AUTOSAR XML (schema 00047)
package /SWC_DEM
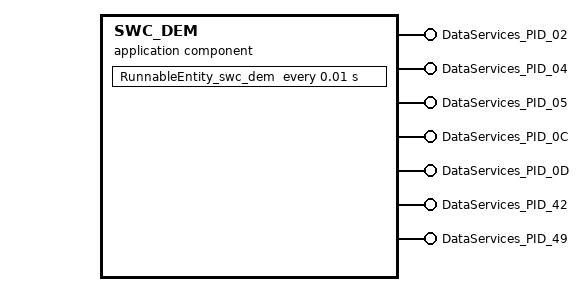
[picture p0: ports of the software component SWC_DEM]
  application sw component type SWC_DEM
    7 x provide port:
      DataServices_PID_02: provided-interface=DataServices_PID_02
      DataServices_PID_04: provided-interface=DataServices_PID_04
      DataServices_PID_05: provided-interface=DataServices_PID_05
      DataServices_PID_0C: provided-interface=DataServices_PID_0C
      DataServices_PID_0D: provided-interface=DataServices_PID_0D
      DataServices_PID_42: provided-interface=DataServices_PID_42
      DataServices_PID_49: provided-interface=DataServices_PID_49
    behavior IB_SWC_DEM
      timing event TimingEvent_SWC_DEM: start-on-event=RunnableEntity_swc_dem, period=0.01
      7 x operation invoked event:
        OperationInvokedEvent_PID_02: start-on-event=ASW_DEM_DataServices_Dem_PID_02, operation=DataServices_PID_02.ReadData
        OperationInvokedEvent_PID_0D: start-on-event=ASW_DEM_DataServices_Dem_PID_0D, operation=DataServices_PID_0D.ReadData
        OperationInvokedEvent_PID_42: start-on-event=ASW_DEM_DataServices_Dem_PID_42, operation=DataServices_PID_42.ReadData
        OperationInvokedEvent_PID_49: start-on-event=ASW_DEM_DataServices_Dem_PID_49, operation=DataServices_PID_49.ReadData
        OperationInvokedEvent_PID_05: start-on-event=ASW_DEM_DataServices_Dem_PID_05, operation=DataServices_PID_05.ReadData
        OperationInvokedEvent_PID_04: start-on-event=ASW_DEM_DataServices_Dem_PID_04, operation=DataServices_PID_04.ReadData
        OperationInvokedEvent_PID_0C: start-on-event=ASW_DEM_DataServices_Dem_PID_0C, operation=DataServices_PID_0C.ReadData
      8 x runnable:
        ASW_DEM_DataServices_Dem_PID_02: symbol=ASW_DEM_DataServices_DemPID_02_ReadData_func
        ASW_DEM_DataServices_Dem_PID_04: symbol=ASW_DEM_DataServices_DemPID_04_ReadData_func
        ASW_DEM_DataServices_Dem_PID_05: symbol=ASW_DEM_DataServices_DemPID_05_ReadData_func
        ASW_DEM_DataServices_Dem_PID_0C: symbol=ASW_DEM_DataServices_DemPID_0C_ReadData_func
        ASW_DEM_DataServices_Dem_PID_0D: symbol=ASW_DEM_DataServices_DemPID_0D_ReadData_func
        ASW_DEM_DataServices_Dem_PID_42: symbol=ASW_DEM_DataServices_DemPID_42_ReadData_func
        ASW_DEM_DataServices_Dem_PID_49: symbol=ASW_DEM_DataServices_DemPID_49_ReadData_func
        RunnableEntity_swc_dem
